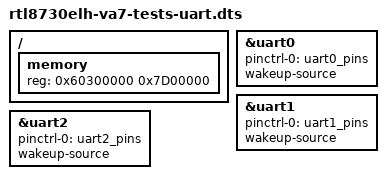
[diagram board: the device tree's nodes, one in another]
// SPDX-License-Identifier: GPL-2.0-only
/*
* Realtek DTS for UART test
*
* Copyright (C) 2023, Realtek Corporation. All rights reserved.
*/

/dts-v1/;

#include "rtl8730e.dtsi"
#include "rtl8730e-spi-nand-128m.dtsi"

/ {
	memory {
		device_type = "memory";
		// DRAM base address should be 1MB-aligned.
		reg = <0x60300000 0x7D00000>;  // 128MB -- exclude 3MB secure memory
	};
};

// Configure peripherals.
&uart0 {
	pinctrl-names = "default";
	pinctrl-0 = <&uart0_pins>;
	wakeup-source;
	status = "okay";
};

&uart1 {
	pinctrl-names = "default";
	pinctrl-0 = <&uart1_pins>;
	wakeup-source;
	status = "okay";
};

&uart2 {
	pinctrl-names = "default";
	pinctrl-0 = <&uart2_pins>;
	wakeup-source;
	status = "okay";
};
